# PIC32CK2051GC00144 register map
Vendor: Microchip Technology; Series: PIC32CKGC00; File version: 0
CPU: CM33 r0p0, little endian, MPU, FPU, DSP, 3 interrupt priority bits, 158 interrupts
Registers are 32-bit, read-write, reset 0x0 unless marked. A register's access mark holds for its fields unless they carry their own. Offsets are from the block's base; [hi:lo] are bit positions; lines under a group give offsets from that group; {n}, {i} and the like mark numbered series.

## ICB — Implementation Control Block
Base 0xE000E000; register names take the prefix ICB_
0x04 ICTR ro — Interrupt Controller Type Register
  [3:0] INTLINESNUM — Interrupt line set number
0x08 ACTLR — Auxiliary Control Register
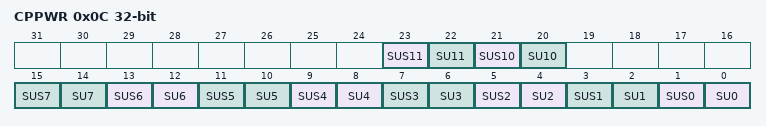
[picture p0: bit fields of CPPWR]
0x0C CPPWR — Coprocessor Power Control Register
  [23] SUS11 — State UNKNOWN Secure only 11
  [22] SU11 — State UNKNOWN 11
  [21] SUS10 — State UNKNOWN Secure only 10
  [20] SU10 — State UNKNOWN 10
  [2n+1] SUS{n} (n=0..7) — State UNKNOWN Secure only {n}
  [2n] SU{n} (n=0..7) — State UNKNOWN {n}

## IDAU — Implementation Defined Attribution Unit
Base 0x4480C000; register names take the prefix IDAU_
0x00 CTRL wo — Control
  [31:16] CMD — Command Register
    0xA501=ENABLE (Module Enable); 0xA502=DISABLE (Module Disable); 0xA503=WLCK (Write Lock)
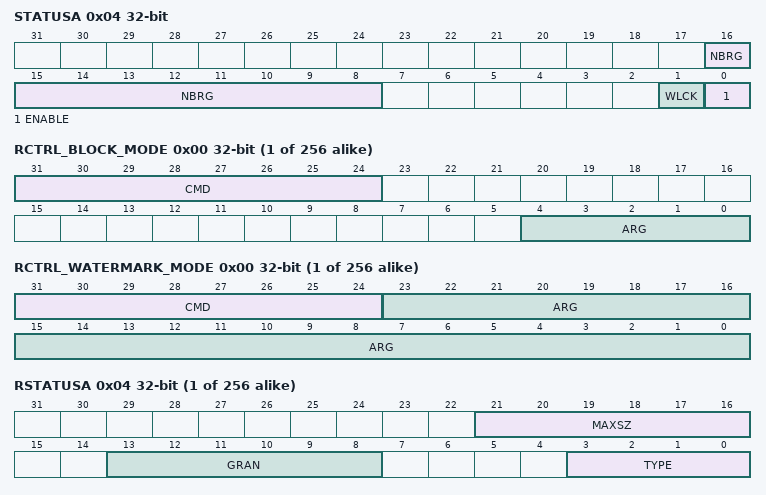
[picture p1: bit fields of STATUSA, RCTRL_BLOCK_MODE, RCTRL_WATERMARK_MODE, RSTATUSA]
0x04 STATUSA ro
  [16:8] NBRG — Number Of IDAU Regions
  [1] WLCK — Write Lock
  [0] ENABLE
0x08 STATUSB
  [0] CFGERR — Configuration Error
{0x1000+0x10*i} REGIONS[{i}] (i=0..255) group
  0x00 RCTRL_BLOCK_MODE wo — Region Control
    [31:24] CMD — Command
      90=CLRNONSEC (Clear IDAU region x Non-Secure State of block ARG (RSTATUSB[x].NONSEC[ARG]=0)); 91=SETNONSEC (Set IDAU region x Non-Secure State of block ARG (RSTATUSB[x].NONSEC[ARG]=1))
    [4:0] ARG — Command Argument (Block ID)
  0x00 RCTRL_WATERMARK_MODE wo (alternate view of RCTRL_BLOCK_MODE) — Region Control
    [31:24] CMD — Command
      92=WRSZ (Write IDAU region x Size (RSTATUSB[x].SIZE=ARG))
    [23:0] ARG — Command Argument (Watermark)
  0x04 RSTATUSA ro — Region Status A
    [21:16] MAXSZ — Command Argument Maximum Size
    [13:8] GRAN — Region Granularity
      0=GRAN_NA (Not Applicable); 5=GRAN_32B; 6=GRAN_64B; 7=GRAN_128B; 8=GRAN_256B; 9=GRAN_512B; 10=GRAN_1KB; 11=GRAN_2KB; 12=GRAN_4KB; 13=GRAN_8KB; 14=GRAN_16KB; 15=GRAN_32KB; 16=GRAN_64KB; 17=GRAN_128KB; 18=GRAN_256KB; 19=GRAN_512KB; 20=GRAN_1MB; 21=GRAN_2MB; 22=GRAN_4MB; 23=GRAN_8MB; 24=GRAN_16MB; 25=GRAN_32MB; 26=GRAN_64MB; 27=GRAN_128MB; 28=GRAN_256MB; 29=GRAN_512MB; 30=GRAN_1GB; 31=GRAN_2GB; 32=GRAN_4GB
    [3:0] TYPE — IDAU Region Type
      0=INVALID (Region is invalid); 1=SEC (Region is secure); 2=NONSEC (Region is non secure); 3=NONSEC_W (Region is non secure, the associated register group implements a watermark configuration); 4=SECnNONSEC_B (Region is either secure or non-secure, the associated register group implements a block configuration); 5=SECnNONSEC_L (Region is either secure or non-secure, configuration is linked to another IDAU region configuration bit (the linked configuration bit identification info is readable from the RSTATUSC register inside the same register group)); 6=NSC_W (Region is non-secure callable, the associated register group implements a watermark configuration); 7=EXEMPT_B (Region is exempt from security, the associated register group implements a block configuration)
  0x08 RSTATUSB_BLOCK_MODE ro — Region Status B
    [31:0] NONSEC — Block Based Region Non-Secure State
  0x08 RSTATUSB_WATERMARK_MODE ro (alternate view of RSTATUSB_BLOCK_MODE) — Region Status B
    [31:0] SIZE — Watermark Based Region Size in Bytes
  0x0C RSTATUSC_BLOCK_MODE ro — Region Status C
    [31:0] CST — Constant Block Configuration
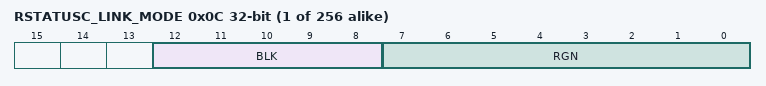
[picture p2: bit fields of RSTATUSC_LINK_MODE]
  0x0C RSTATUSC_LINK_MODE ro (alternate view of RSTATUSC_BLOCK_MODE) — Region Status C
    [12:8] BLK — Linked IDAU Region Block ID
    [7:0] RGN — Linked IDAU Region ID

## MCLK — Main Clock
Base 0x44012000; register names take the prefix MCLK_
0x00 INTENCLR — Interrupt Enable Clear
  [0] CKRDY — Clock Ready Interrupt Enable
0x04 INTENSET — Interrupt Enable Set
  [0] CKRDY — Clock Ready Interrupt Enable
0x08 INTFLAG reset 0x1 — Interrupt Flag Status and Clear
  [0] CKRDY — Clock Ready
0x0C CLKDIV — Clock Divider Control
  [7:0] DIV — Clock Domain Division Factor
    1=Divide by 1; 2=Divide by 2; 4=Divide by 4; 8=Divide by 8; 16=Divide by 16; 32=Divide by 32; 64=Divide by 64; 128=Divide by 128
{0x3C+4i} CLKMSK[{i}] (i=0..8) — Peripheral Clock Enable Mask
  [31:0] MASK

## Notices in the file
Copyright (c) 2022 Microchip Technology Inc.
SPDX-License-Identifier: Apache-2.0
Licensed under the Apache License, Version 2.0 (the "License");
you may not use this file except in compliance with the License.
You may obtain a copy of the License at
http://www.apache.org/licenses/LICENSE-2.0
Unless required by applicable law or agreed to in writing, software
distributed under the License is distributed on an "AS IS" BASIS,
WITHOUT WARRANTIES OR CONDITIONS OF ANY KIND, either express or implied.
See the License for the specific language governing permissions and
limitations under the License.
